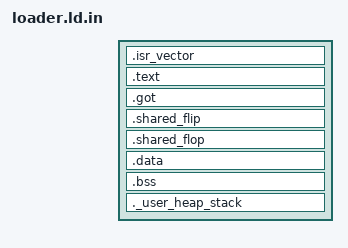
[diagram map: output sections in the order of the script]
/* ldr.ld */

/* Entry Point */
ENTRY(Reset_Handler)


_estack = 0x20002000;
/* */
INCLUDE BUILDDIR/layout.ld


/* Define output sections */
SECTIONS
{
  /* The startup code goes first into FLASH */
  .isr_vector :
  {
    . = ALIGN(4);
    KEEP(*(.isr_vector)) /* Startup code */
    . = ALIGN(4);
  } >LDR

  /* The program code and other data goes into FLASH */
  .text :
  {
    _stext = .;	            /* create a global symbol at data start */
    *startup*(.text.Reset_Handler)
    *(.text*)
    *(.rodata*)         /* .rodata sections (constants, strings, etc.) */
    *(.glue_7*)         /* glue arm to thumb code */
    *(.glue_7t*)        /* glue thumb to arm code */
	*(.eh_frame*)

    KEEP (*(.init))
    KEEP (*(.fini))

    . = ALIGN(4);
    _etext = .;        /* define a global symbols at end of code */
    _exit = .;
  } >LDR

  /* used by the startup to initialize got */
  _sigot = .;
  .got : AT ( _sigot ) {
    . = ALIGN(4);
        _sgot = .;
        /*  *(.got.plt)
         *    We don't need plt segment
         *    since we do not need dynamic library relocation
         */
        *(.got)
    . = ALIGN(4);
    _egot = .;
  } >LDR

  /* Shared variables */
  .shared_flip :    {
    . = ALIGN(4);
    KEEP(*(.shared_flip)) ;
  }>SHR_FLIP

  .shared_flop :    {
    . = ALIGN(4);
    KEEP(*(.shared_flop)) ;
  }>SHR_FLOP


  /* used by the startup to initialize data */
  _sidata = .;

  /* Initialized data sections goes into RAM, load LMA copy after code */
  .data : AT ( _sidata )
  {
    . = ALIGN(4);
    _sdata = .;        /* create a global symbol at data start */
    *(.data)           /* .data sections */
    *(.data*)          /* .data* sections */

    . = ALIGN(4);
    _edata = .;        /* define a global symbol at data end */
  } >RAM_USER


  /* Uninitialized data section */
  . = ALIGN(4);
  .bss :
  {
    /* This is used by the startup in order to initialize the .bss secion */
    _sbss = .;         /* define a global symbol at bss start */
    __bss_start__ = _sbss;
    *debug.o(.bss)
    *(.bss)
    *(.bss*)
    *(COMMON)

    . = ALIGN(4);
    _ebss = .;         /* define a global symbol at bss end */
    __bss_end__ = _ebss;
  } >RAM_USER

    /* User_heap_stack section, used to check that there is enough RAM left */
  ._user_heap_stack :
  {
    . = ALIGN(4);
    PROVIDE ( end = . );
    PROVIDE ( _end = . );
    . = . + _Min_Heap_Size;
    . = . + _Min_Stack_Size;
    . = ALIGN(4);
  } >RAM_USER

  /* Remove information from the standard libraries */
  /DISCARD/ :
  {
    libgcc.a ( * )
  }

}
